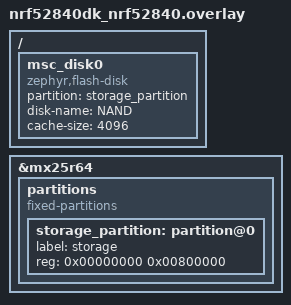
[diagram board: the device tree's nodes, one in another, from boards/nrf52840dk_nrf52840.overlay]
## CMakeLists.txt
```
# SPDX-License-Identifier: Apache-2.0

cmake_minimum_required(VERSION 3.20.0)
find_package(Zephyr REQUIRED HINTS $ENV{ZEPHYR_BASE})
project(mass)

include(${ZEPHYR_BASE}/samples/subsys/usb/common/common.cmake)

FILE(GLOB app_sources src/*.c)
target_sources(app PRIVATE ${app_sources})



if(CONFIG_BUILD_WITH_TFM)
  target_include_directories(app PRIVATE
    $<TARGET_PROPERTY:tfm,TFM_BINARY_DIR>/api_ns/interface/include
  )
endif()
```

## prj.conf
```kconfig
CONFIG_STDOUT_CONSOLE=y

#USB related configs
CONFIG_USB_DEVICE_STACK=y
CONFIG_USB_DEVICE_PRODUCT="Zephyr MSC sample"
CONFIG_USB_DEVICE_PID=0x0008
CONFIG_LOG=y
CONFIG_USB_DRIVER_LOG_LEVEL_ERR=y
CONFIG_USB_MASS_STORAGE=y
CONFIG_USB_DEVICE_LOG_LEVEL_ERR=y
CONFIG_USB_MASS_STORAGE_LOG_LEVEL_ERR=y
CONFIG_USB_DEVICE_INITIALIZE_AT_BOOT=n

CONFIG_MAIN_STACK_SIZE=1536


CONFIG_SHELL=y
CONFIG_SHELL_PROMPT_UART="AUDIOFS>"
CONFIG_I2S=y


CONFIG_FILE_SYSTEM=y


#CONFIG_APP_MSC_STORAGE_FLASH_FATFS=y
#CONFIG_FS_FATFS_LFN=y
#CONFIG_FLASH=y
#CONFIG_FLASH_JESD216_API=y
```

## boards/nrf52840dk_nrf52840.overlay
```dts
/*
 * Copyright (c) 2019 Peter Bigot Consulting, LLC
 *
 * SPDX-License-Identifier: Apache-2.0
 */

/delete-node/ &storage_partition;

&mx25r64 {
	partitions {
		compatible = "fixed-partitions";
		#address-cells = <1>;
		#size-cells = <1>;

		storage_partition: partition@0 {
			label = "storage";
			reg = <0x00000000 0x00800000>;
		};
	};
};

/ {
	msc_disk0 {
		compatible = "zephyr,flash-disk";
		partition = <&storage_partition>;
		disk-name = "NAND";
		cache-size = <4096>;
	};
};
```

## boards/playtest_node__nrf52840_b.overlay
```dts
/*
 * Copyright (c) 2019 Peter Bigot Consulting, LLC
 *
 * SPDX-License-Identifier: Apache-2.0
 */

/delete-node/ &storage_partition;

&w25q128jv {
	partitions {
		compatible = "fixed-partitions";
		#address-cells = <1>;
		#size-cells = <1>;

		storage_partition: partition@0 {
			label = "storage";
			reg = <0x00000000 0x00800000>;
		};
	};
};

/ {
	msc_disk0 {
		compatible = "zephyr,flash-disk";
		partition = <&storage_partition>;
		disk-name = "NAND";
		cache-size = <4096>;
	};
};
```

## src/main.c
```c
/*
 * Copyright (c) 2016 Intel Corporation.
 * Copyright (c) 2019-2020 Nordic Semiconductor ASA
 *
 * SPDX-License-Identifier: Apache-2.0
 */

#include <sample_usbd.h>

#include <zephyr/kernel.h>
#include <zephyr/logging/log.h>
#include <zephyr/usb/usb_device.h>
#include <zephyr/usb/usbd.h>
#include <zephyr/usb/class/usbd_msc.h>
#include <zephyr/fs/fs.h>
#include <stdio.h>
#include <zephyr/storage/flash_map.h>
#include <ff.h>
#include "audiofs.h"
#include <zephyr/shell/shell.h>

#define STORAGE_PARTITION			storage_partition
#define STORAGE_PARTITION_ID		FIXED_PARTITION_ID(STORAGE_PARTITION)




LOG_MODULE_REGISTER(main);


static int setup_flash(struct fs_mount_t *mnt)
{
	int rc = 0;
	unsigned int id;
	const struct flash_area *pfa;

	mnt->storage_dev = (void *)STORAGE_PARTITION_ID;
	id = STORAGE_PARTITION_ID;

	rc = flash_area_open(id, &pfa);
	printk("Area %u at 0x%x on %s for %u bytes\n",
	       id, (unsigned int)pfa->fa_off, pfa->fa_dev->name,
	       (unsigned int)pfa->fa_size);

	if (rc < 0 && IS_ENABLED(CONFIG_APP_WIPE_STORAGE)) {
		printk("Erasing flash area ... ");
		rc = flash_area_flatten(pfa, 0, pfa->fa_size);
		printk("%d\n", rc);
	}

	if (rc < 0) {
		flash_area_close(pfa);
	}
	return rc;
}

static int mount_app_fs(struct fs_mount_t *mnt)
{
	int rc;
	static FATFS fat_fs;

	mnt->type = FS_FATFS;
	mnt->fs_data = &fat_fs;
	mnt->mnt_point = "/NAND:";

	rc = fs_mount(mnt);

	return rc;
}

static void setup_disk(void)
{
	struct fs_mount_t *mp = &fs_mnt;
	struct fs_dir_t dir;
	struct fs_statvfs sbuf;
	int rc;

	fs_dir_t_init(&dir);

	rc = setup_flash(mp);
	if (rc < 0) {
		LOG_ERR("Failed to setup flash area");
		return;
	}


	rc = mount_app_fs(mp);
	if (rc < 0) {
		LOG_ERR("Failed to mount filesystem");
		return;
	}

	/* Allow log messages to flush to avoid interleaved output */
	k_sleep(K_MSEC(50));

	printk("Mount %s: %d\n", fs_mnt.mnt_point, rc);

	rc = fs_statvfs(mp->mnt_point, &sbuf);
	if (rc < 0) {
		printk("FAIL: statvfs: %d\n", rc);
		return;
	}

	printk("%s: bsize = %lu ; frsize = %lu ;"
	       " blocks = %lu ; bfree = %lu\n",
	       mp->mnt_point,
	       sbuf.f_bsize, sbuf.f_frsize,
	       sbuf.f_blocks, sbuf.f_bfree);

	rc = fs_opendir(&dir, mp->mnt_point);
	printk("%s opendir: %d\n", mp->mnt_point, rc);


	if (rc < 0) {
		LOG_ERR("Failed to open directory");
	}

	while (rc >= 0) {
		struct fs_dirent ent = { 0 };

		rc = fs_readdir(&dir, &ent);

		if (ent.name[0] == 0) {
			printk("End of files\n");
			break;
		}

		printk("  %c \t%u \t%s\n",
		       (ent.type == FS_DIR_ENTRY_FILE) ? 'F' : 'D',
		       ent.size,
		       ent.name);
	}


	(void)fs_closedir(&dir);


	return;
}




/******************************************* SHELL COMMANDS ********************************************/
static int play_wave_file_handler(const struct shell *shell, size_t argc, char **argv)
{
//	if (argc == 6)
//	{
//		play_audio_file(atoi(argv[1]), atoi(argv[2]), atoi(argv[3]), atoi(argv[4]), atoi(argv[5]));
//	}

	shell_fprintf(shell, SHELL_VT100_COLOR_YELLOW, "Playing file: %s\n", argv[1]);
//	audiofs__play_file(argv[1]);
	return 0;
}

static int read_available_files_handler(const struct shell *shell, size_t argc, char **argv)
{
//	audiofs__read_available_files();
	return 0;
}

SHELL_CMD_REGISTER(play_wave_file, NULL, "Play .wav file", play_wave_file_handler);
SHELL_CMD_REGISTER(ls, NULL, "Play .wav file", read_available_files_handler);



int main(void)
{
	int ret;
	
	LOG_INF("ON");

	setup_disk();

	ret = usb_enable(NULL);

	if (ret != 0) {
		LOG_ERR("Failed to enable USB");
		return 0;
	}

	LOG_INF("The device is put in USB mass storage mode.\n");


//	audiofs__i2s_init();

//	audiofs__read_available_files();
//
//	// Check all the existing items in the system
//	audiofs__read_header_basic_info("celeb.wav");
//
//	k_sleep(K_MSEC(1000));
//	audiofs__read_n_samples("crckt.wav", 25);

//	audiofs__play_file("celeb.wav");

	return 0;
}
```

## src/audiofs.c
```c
#include "audiofs.h"
#include <zephyr/fs/fs.h>
#include <stdio.h>
#include <zephyr/logging/log.h>
#include <zephyr/kernel.h>
#include <zephyr/drivers/gpio.h>


#define CONFIG__SAMPLE_FREQUENCY 16000
#define CONFIG__SAMPLE_BIT_WIDTH 16
#define CONFIG__BYTES_PER_SAMPLE sizeof(int16_t)
#define CONFIG__NUMBER_OF_CHANNELS 1
#define CONFIG__SAMPLES_PER_BLOCK 1600                                    // 100ms time per block
#define BLOCK_SIZE (CONFIG__BYTES_PER_SAMPLE * CONFIG__SAMPLES_PER_BLOCK) // 3200 bytes, 1600 samples of 2 bytes
#define CONFIG__TIMEOUT 250 //block duration

#define WAV_HEADER_SIZE 44


LOG_MODULE_REGISTER(audiofs);
K_MEM_SLAB_DEFINE_STATIC(i2s_mem_slab, BLOCK_SIZE, 2, 4); // Memory slabs for I2S_TX queue, 2 blocks of 3200 bytes

// Audio variables
const struct device *const i2s_dev_tx = DEVICE_DT_GET(DT_NODELABEL(i2s_rxtx));
struct i2s_config i2s_configurations;

static struct gpio_dt_spec amp1_sd_pin = GPIO_DT_SPEC_GET(DT_ALIAS(amp1_sd), gpios);
#ifdef CONFIG_BOARD_PLAYTEST_NODE__NRF52840_B
static struct gpio_dt_spec amp2_sd_pin = GPIO_DT_SPEC_GET(DT_ALIAS(amp2_sd), gpios);
#endif

uint8_t data_block[BLOCK_SIZE]; // Audio buffer
int16_t audio_block[CONFIG__SAMPLES_PER_BLOCK]; // Audio buffer ptr


#define CONFIG__SOUND_TH_STACK_SIZE (500 * 10)	//could be tunned
#define CONFIG__SOUND_TH_PRIORITY 5
void sound_thread_task(void *, void *, void *);
K_THREAD_DEFINE(sound_thread, CONFIG__SOUND_TH_STACK_SIZE,
                sound_thread_task, NULL, NULL, NULL,
                CONFIG__SOUND_TH_PRIORITY, 0, 0);


// FS variables
struct fs_mount_t fs_mnt;


void audiofs__i2s_init()
{
	int ret;

    gpio_pin_configure_dt(&amp1_sd_pin, GPIO_OUTPUT);
    //audio__amp_state(1, 1);

#ifdef CONFIG_BOARD_PLAYTEST_NODE__NRF52840_B
    gpio_pin_configure_dt(&amp2_sd_pin, GPIO_OUTPUT);
    //audio__amp_state(2, 0);
#endif

    i2s_configurations.word_size = CONFIG__SAMPLE_BIT_WIDTH;
    i2s_configurations.channels = CONFIG__NUMBER_OF_CHANNELS;
    i2s_configurations.format = I2S_FMT_DATA_FORMAT_I2S;
    i2s_configurations.options = I2S_OPT_BIT_CLK_MASTER | I2S_OPT_FRAME_CLK_MASTER;
    i2s_configurations.frame_clk_freq = CONFIG__SAMPLE_FREQUENCY;
    i2s_configurations.mem_slab = &i2s_mem_slab;
    i2s_configurations.block_size = BLOCK_SIZE;
    i2s_configurations.timeout = CONFIG__TIMEOUT;

    ret = i2s_configure(i2s_dev_tx, I2S_DIR_TX, &i2s_configurations);
    if (ret < 0)
    {
        LOG_ERR("Audio not ready \n");
    }

    LOG_INF("I2S ready\n");
}



void audiofs__read_available_files()
{
	struct fs_mount_t *mp = &fs_mnt;
	struct fs_dir_t dir;
	int rc;

	fs_dir_t_init(&dir);
	rc = fs_opendir(&dir, mp->mnt_point);
	
	printk("%s opendir: %d\n", mp->mnt_point, rc);

	if (rc < 0)
	{
		LOG_ERR("Failed to open directory");
	}


	LOG_INF("Type \tSize \tName");

	while (rc >= 0)
	{
		struct fs_dirent ent = {0};

		rc = fs_readdir(&dir, &ent);
		if (ent.name[0] == 0)
		{
			break;
		}
		LOG_INF("%c \t%u \t%s", (ent.type == FS_DIR_ENTRY_FILE) ? 'F' : 'D', ent.size, ent.name);
	}

	(void)fs_closedir(&dir);
}


uint8_t file_path[50];

void audiofs__play_file(char *file_name)
{

	// absolute path to the file
	sprintf(file_path, "/NAND:/%s", file_name);
	k_thread_resume(sound_thread);

}


void apply_block_volume(int16_t *block, uint32_t block_size, uint32_t volume) 
{
	for(uint32_t i = 0; i < block_size; i++)
	{
		block[i] = ((int32_t)block[i] * (int32_t)volume) >> 8;
    	//return ((int32_t)sample * (int32_t)actual_audio.volume) >> 8; // 8 bit volume control
	}
}


/*
    _  _   _ ___ ___ ___  ___ ___   _____ _  _ ___ ___   _   ___  
   /_\| | | |   \_ _/ _ \| __/ __| |_   _| || | _ \ __| /_\ |   \ 
  / _ \ |_| | |) | | (_) | _|\__ \   | | | __ |   / _| / _ \| |) |
 /_/ \_\___/|___/___\___/|_| |___/   |_| |_||_|_|_\___/_/ \_\___/ 

*/                                                                  

void sound_thread_task(void *, void *, void *)
{
	struct fs_file_t audio_file;
	uint32_t read_bytes;
	sub_chunk_data_t metadata_chunk;
	
    while (1){

		k_thread_suspend(sound_thread);


		fs_file_t_init(&audio_file);

		if (fs_open(&audio_file, file_path, FS_O_READ) < 0)
		{
			LOG_ERR("Failed to open %s\n", file_path);
			return;
		}

		// /////////////////////////////////////////////////////////////////
		// Read .wav file header and metadata
		read_bytes = fs_read(&audio_file, data_block, WAV_HEADER_SIZE);
		memcpy(&metadata_chunk, &data_block[36], sizeof(sub_chunk_data_t));	// Read chunk info

		// Iterate until find the data chunk	
		while(memcmp(metadata_chunk.id, "data", 4))
		{
			read_bytes = fs_read(&audio_file, data_block, metadata_chunk.size);		// Read chunk data
			read_bytes = fs_read(&audio_file, data_block, sizeof(sub_chunk_data_t));	// Read chunk info
			memcpy(&metadata_chunk, data_block, sizeof(sub_chunk_data_t));
		}


		// First block filled with zeros
		memset(audio_block, 0, BLOCK_SIZE);
		i2s_write_block(i2s_dev_tx, audio_block);
		if (!i2s_trigger_cmd(i2s_dev_tx, I2S_TRIGGER_START)){
			return;
		}

		// Read samples from the file and play them
		while(read_bytes > 0)
		{	
			apply_block_volume(audio_block, BLOCK_SIZE, 0xff);
			i2s_write_block(i2s_dev_tx, audio_block);
			read_bytes = fs_read(&audio_file, audio_block, BLOCK_SIZE);
		}

		if (!i2s_trigger_cmd(i2s_dev_tx, I2S_TRIGGER_STOP)){    // Wait the end of transmision and stop audio streaming
			return;
		}

		fs_close(&audio_file);	

       

    }
}


/*
  ___ ___ ___   ___ _   _ _  _  ___ _____ ___ ___  _  _ ___ 
 |_ _|_  ) __| | __| | | | \| |/ __|_   _|_ _/ _ \| \| / __|
  | | / /\__ \ | _|| |_| | .` | (__  | |  | | (_) | .` \__ \
 |___/___|___/ |_|  \___/|_|\_|\___| |_| |___\___/|_|\_|___/
                                                            
*/

bool i2s_trigger_cmd(const struct device *i2s_dev_tx, enum i2s_trigger_cmd cmd)
{
    int ret;

    ret = i2s_trigger(i2s_dev_tx, I2S_DIR_TX, cmd);
    if (ret < 0)
    {
        LOG_ERR("Failed to trigger command %d on TX: %d\n", cmd, ret);
        return false;
    }

    return true;
}


bool i2s_write_block(const struct device *i2s_dev_tx, int16_t *sound_block)
{
    int ret = 1;

    //Waiting for the I2S state to come out of the stopping state 
    while(ret != 0){
        ret = i2s_buf_write(i2s_dev_tx, sound_block, BLOCK_SIZE);
    }

    return true;
}
```

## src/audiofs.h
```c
#ifndef AUDIOFS_H_
#define AUDIOFS_H_

#include <inttypes.h>
#include <stdbool.h>
#include <zephyr/drivers/i2s.h>


typedef struct 
{
    char id [4];
    uint32_t size;
} sub_chunk_data_t;


extern struct fs_mount_t fs_mnt;

extern void audiofs__i2s_init();
extern void audiofs__read_available_files();
extern void audiofs__read_header_basic_info(char * file_name);
extern void audiofs__read_n_samples(char *file_name, uint32_t n);

extern void audiofs__play_file(char *file_name);


bool i2s_trigger_cmd(const struct device *i2s_dev_tx, enum i2s_trigger_cmd cmd);
bool i2s_write_block(const struct device *i2s_dev_tx, int16_t* sound_block);

#endif
```
